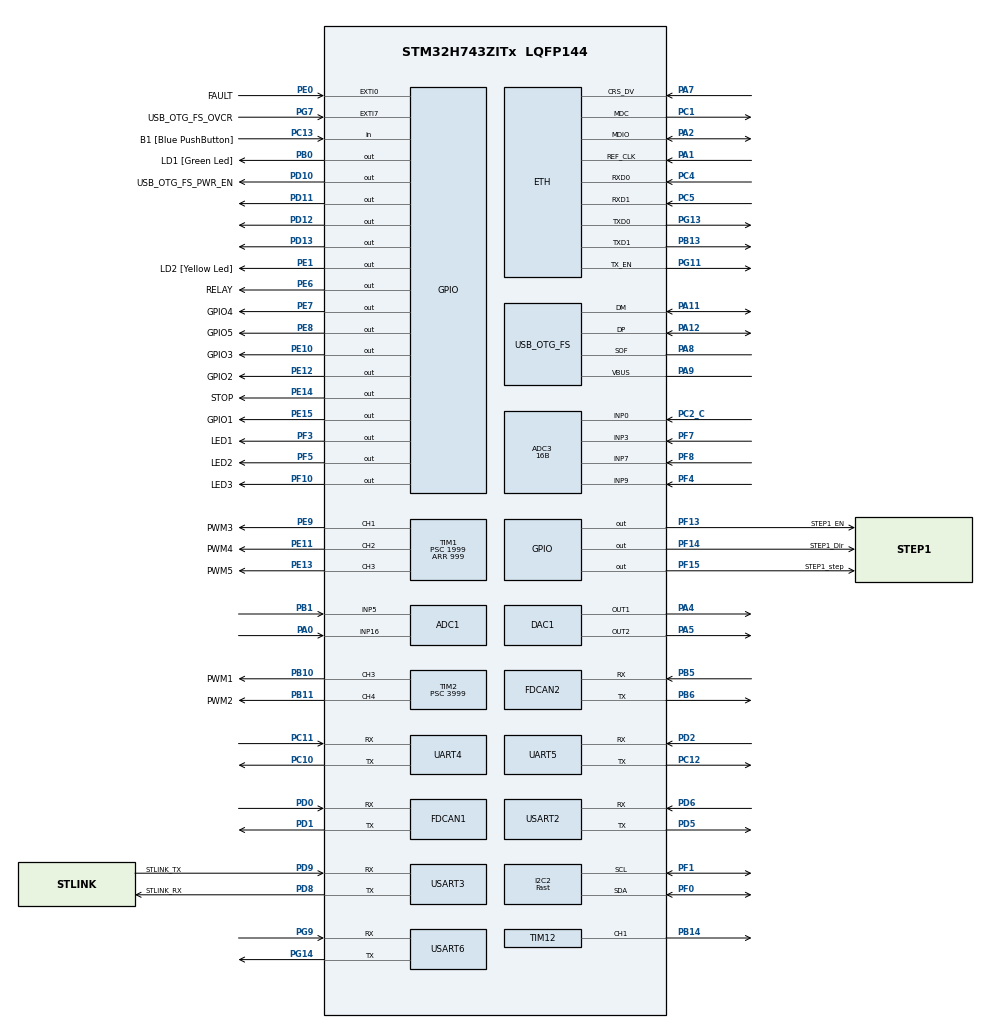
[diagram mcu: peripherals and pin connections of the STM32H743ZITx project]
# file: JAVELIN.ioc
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ADC1.Channel-0\#ChannelRegularConversion=ADC_CHANNEL_5
ADC1.NbrOfConversionFlag=1
ADC1.OffsetNumber-0\#ChannelRegularConversion=ADC_OFFSET_NONE
ADC1.OffsetSignedSaturation-0\#ChannelRegularConversion=DISABLE
ADC1.Rank-0\#ChannelRegularConversion=1
ADC1.SamplingTime-0\#ChannelRegularConversion=ADC_SAMPLETIME_1CYCLE_5
ADC1.master=1
ADC3.Channel-23\#ChannelRegularConversion=ADC_CHANNEL_TEMPSENSOR
ADC3.Channel-24\#ChannelRegularConversion=ADC_CHANNEL_VBAT
ADC3.Channel-25\#ChannelRegularConversion=ADC_CHANNEL_VREFINT
ADC3.ClockPrescalerADC3=ADC_CLOCK_ASYNC_DIV1
ADC3.NbrOfConversion=3
ADC3.NbrOfConversionFlag=1
ADC3.OffsetNumber-23\#ChannelRegularConversion=ADC_OFFSET_NONE
ADC3.OffsetNumber-24\#ChannelRegularConversion=ADC_OFFSET_NONE
ADC3.OffsetNumber-25\#ChannelRegularConversion=ADC_OFFSET_NONE
ADC3.OffsetSignedSaturation-23\#ChannelRegularConversion=DISABLE
ADC3.OffsetSignedSaturation-24\#ChannelRegularConversion=DISABLE
ADC3.OffsetSignedSaturation-25\#ChannelRegularConversion=DISABLE
ADC3.OversamplingMode=ENABLE
ADC3.Rank-23\#ChannelRegularConversion=1
ADC3.Rank-24\#ChannelRegularConversion=2
ADC3.Rank-25\#ChannelRegularConversion=3
ADC3.Ratio=2
ADC3.Resolution=ADC_RESOLUTION_16B
ADC3.SamplingTime-23\#ChannelRegularConversion=ADC_SAMPLETIME_387CYCLES_5
ADC3.SamplingTime-24\#ChannelRegularConversion=ADC_SAMPLETIME_32CYCLES_5
ADC3.SamplingTime-25\#ChannelRegularConversion=ADC_SAMPLETIME_32CYCLES_5
CORTEX_M7.AccessPermission-Cortex_Memory_Protection_Unit_Region0_Settings=MPU_REGION_FULL_ACCESS
CORTEX_M7.AccessPermission-Cortex_Memory_Protection_Unit_Region1_Settings=MPU_REGION_FULL_ACCESS
CORTEX_M7.BaseAddress-Cortex_Memory_Protection_Unit_Region0_Settings=0x30040000
CORTEX_M7.BaseAddress-Cortex_Memory_Protection_Unit_Region1_Settings=0x30040000
CORTEX_M7.CPU_DCache=Enabled
CORTEX_M7.CPU_ICache=Enabled
CORTEX_M7.DisableExec-Cortex_Memory_Protection_Unit_Region0_Settings=MPU_INSTRUCTION_ACCESS_DISABLE
CORTEX_M7.DisableExec-Cortex_Memory_Protection_Unit_Region1_Settings=MPU_INSTRUCTION_ACCESS_DISABLE
CORTEX_M7.Enable-Cortex_Memory_Protection_Unit_Region0_Settings=MPU_REGION_ENABLE
CORTEX_M7.Enable-Cortex_Memory_Protection_Unit_Region1_Settings=MPU_REGION_ENABLE
CORTEX_M7.IsBufferable-Cortex_Memory_Protection_Unit_Region1_Settings=MPU_ACCESS_BUFFERABLE
CORTEX_M7.IsShareable-Cortex_Memory_Protection_Unit_Region1_Settings=MPU_ACCESS_SHAREABLE
CORTEX_M7.MPU_Control=MPU_PRIVILEGED_DEFAULT
CORTEX_M7.Size-Cortex_Memory_Protection_Unit_Region0_Settings=MPU_REGION_SIZE_32KB
CORTEX_M7.Size-Cortex_Memory_Protection_Unit_Region1_Settings=MPU_REGION_SIZE_256B
CORTEX_M7.TypeExtField-Cortex_Memory_Protection_Unit_Region0_Settings=MPU_TEX_LEVEL1
DAC1.DAC_Channel-DAC_OUT1=DAC_CHANNEL_1
DAC1.DAC_Channel-DAC_OUT2=DAC_CHANNEL_2
ETH.MediaInterface=HAL_ETH_RMII_MODE
FDCAN1.CalculateBaudRateNominal=312500
FDCAN1.CalculateTimeBitNominal=3200
FDCAN1.CalculateTimeQuantumNominal=640.0
FDCAN2.CalculateBaudRateNominal=312500
FDCAN2.CalculateTimeBitNominal=3200
FDCAN2.CalculateTimeQuantumNominal=640.0
FREERTOS.Queues01=RX_msg_queue,32,uint16_t,0,Dynamic,NULL,NULL
FREERTOS.Tasks01=defaultTask,24,256,StartDefaultTask,Default,NULL,Dynamic,NULL,NULL;Blink,8,128,Blink_Init,Default,NULL,Dynamic,NULL,NULL;IDWGTrigger,40,128,IDWGTrigger_Init,Default,NULL,Dynamic,NULL,NULL;ADCPoll,8,128,ADCPoll_Init,Default,NULL,Dynamic,NULL,NULL;PSFunctions,8,128,PSFunctions_Init,Default,NULL,Dynamic,NULL,NULL;SSFunctions,8,128,SSFunctions_Init,Default,NULL,Dynamic,NULL,NULL;DSFunctions,8,128,DSFunctions_Init,Default,NULL,Dynamic,NULL,NULL
FREERTOS.configENABLE_FPU=1
FREERTOS.configGENERATE_RUN_TIME_STATS=1
FREERTOS.configRECORD_STACK_HIGH_ADDRESS=1
FREERTOS.configTOTAL_HEAP_SIZE=65536
FREERTOS.configUSE_NEWLIB_REENTRANT=1
FREERTOS.configUSE_STATS_FORMATTING_FUNCTIONS=1
I2C2.I2C_Speed_Mode=I2C_Fast
I2C2.Timing=0x009034B6
IWDG1.Prescaler=IWDG_PRESCALER_16
LWIP.BSP.number=1
LWIP.CHECKSUM_CHECK_TCP=1
LWIP.CHECKSUM_GEN_TCP=1
LWIP.DEFAULT_THREAD_STACKSIZE=16360
LWIP.GATEWAY_ADDRESS=192.168.000.001
LWIP.IP_ADDRESS=192.168.000.123
LWIP.LWIP_DHCP=0
LWIP.MEM_SIZE=16360
LWIP.NETMASK_ADDRESS=255.255.255.000
LWIP.PBUF_POOL_BUFSIZE=16360
LWIP.PBUF_POOL_SIZE=12
LWIP.Version=v2.1.2_Cube
LWIP0.BSP.STBoard=false
LWIP0.BSP.api=BSP_COMPONENT_DRIVER
LWIP0.BSP.component=LAN8742
LWIP0.BSP.instance=LAN8742
LWIP0.BSP.name=Driver_PHY
LWIP0.BSP.semaphore=S_LAN8742
LWIP0.BSP.solution=LAN8742
Mcu.Family=STM32H7
Mcu.Name=STM32H743ZITx
Mcu.Package=LQFP144
NVIC.ETH_IRQn=true\:5\:0\:false\:false\:true\:true\:true\:true\:true
NVIC.PriorityGroup=NVIC_PRIORITYGROUP_4
NVIC.TIM16_IRQn=true\:5\:0\:false\:false\:true\:true\:true\:true\:true
NVIC.TIM17_IRQn=true\:15\:0\:false\:false\:true\:false\:false\:true\:true
NVIC.TimeBase=TIM17_IRQn
NVIC.TimeBaseIP=TIM17
PA0.Mode=IN16-Single-Ended
PA0.Signal=ADC1_INP16
PA1.GPIO_Speed=GPIO_SPEED_FREQ_VERY_HIGH
PA1.Mode=RMII
PA1.Signal=ETH_REF_CLK
PA11.Mode=Device_Only
PA11.Signal=USB_OTG_FS_DM
PA12.Mode=Device_Only
PA12.Signal=USB_OTG_FS_DP
PA13\ (JTMS/SWDIO).Mode=Serial_Wire
PA13\ (JTMS/SWDIO).Signal=DEBUG_JTMS-SWDIO
PA14\ (JTCK/SWCLK).Mode=Serial_Wire
PA14\ (JTCK/SWCLK).Signal=DEBUG_JTCK-SWCLK
PA2.GPIO_Speed=GPIO_SPEED_FREQ_VERY_HIGH
PA2.Mode=RMII
PA2.Signal=ETH_MDIO
PA4.Signal=COMP_DAC11_group
PA5.Signal=COMP_DAC12_group
PA7.GPIO_Speed=GPIO_SPEED_FREQ_VERY_HIGH
PA7.Mode=RMII
PA7.Signal=ETH_CRS_DV
PA8.Mode=Activate_SOF_FS
PA8.Signal=USB_OTG_FS_SOF
PA9.Mode=Activate_VBUS
PA9.Signal=USB_OTG_FS_VBUS
PB0.GPIO_Label=LD1 [Green Led]
PB0.Signal=GPIO_Output
PB1.Signal=ADCx_INP5
PB10.GPIO_Label=PWM1
PB10.Signal=S_TIM2_CH3
PB11.GPIO_Label=PWM2
PB11.Signal=S_TIM2_CH4
PB13.GPIO_Speed=GPIO_SPEED_FREQ_VERY_HIGH
PB13.Mode=RMII
PB13.Signal=ETH_TXD1
PB14.Signal=S_TIM12_CH1
PB5.Mode=FDCAN_Activate
PB5.Signal=FDCAN2_RX
PB6.Mode=FDCAN_Activate
PB6.Signal=FDCAN2_TX
PC1.GPIO_Speed=GPIO_SPEED_FREQ_VERY_HIGH
PC1.Mode=RMII
PC1.Signal=ETH_MDC
PC10.Mode=Asynchronous
PC10.Signal=UART4_TX
PC11.Mode=Asynchronous
PC11.Signal=UART4_RX
PC12.Mode=Asynchronous
PC12.Signal=UART5_TX
PC13.GPIO_Label=B1 [Blue PushButton]
PC13.Signal=GPIO_Input
PC14-OSC32_IN\ (OSC32_IN).Mode=LSE-External-Oscillator
PC14-OSC32_IN\ (OSC32_IN).Signal=RCC_OSC32_IN
PC15-OSC32_OUT\ (OSC32_OUT).Mode=LSE-External-Oscillator
PC15-OSC32_OUT\ (OSC32_OUT).Signal=RCC_OSC32_OUT
PC2_C.Mode=IN0-Single-Ended
PC2_C.Signal=ADC3_INP0
PC4.GPIO_Speed=GPIO_SPEED_FREQ_VERY_HIGH
PC4.Mode=RMII
PC4.Signal=ETH_RXD0
PC5.GPIO_Speed=GPIO_SPEED_FREQ_VERY_HIGH
PC5.Mode=RMII
PC5.Signal=ETH_RXD1
PD0.Mode=FDCAN_Activate
PD0.Signal=FDCAN1_RX
PD1.Mode=FDCAN_Activate
PD1.Signal=FDCAN1_TX
PD10.GPIO_Label=USB_OTG_FS_PWR_EN
PD10.Signal=GPIO_Output
PD11.Signal=GPIO_Output
PD12.Signal=GPIO_Output
PD13.Signal=GPIO_Output
PD2.Mode=Asynchronous
PD2.Signal=UART5_RX
PD5.Mode=Asynchronous
PD5.Signal=USART2_TX
PD6.Mode=Asynchronous
PD6.Signal=USART2_RX
PD8.GPIO_Label=STLINK_RX
PD8.Mode=Asynchronous
PD8.Signal=USART3_TX
PD9.GPIO_Label=STLINK_TX
PD9.Mode=Asynchronous
PD9.Signal=USART3_RX
PE0.GPIO_Label=FAULT
PE0.Signal=GPXTI0
PE1.GPIO_Label=LD2 [Yellow Led]
PE1.Signal=GPIO_Output
PE10.GPIO_Label=GPIO3
PE10.Signal=GPIO_Output
PE11.GPIO_Label=PWM4
PE11.Signal=S_TIM1_CH2
PE12.GPIO_Label=GPIO2
PE12.Signal=GPIO_Output
PE13.GPIO_Label=PWM5
PE13.Signal=S_TIM1_CH3
PE14.GPIO_Label=STOP
PE14.Signal=GPIO_Output
PE15.GPIO_Label=GPIO1
PE15.Signal=GPIO_Output
PE6.GPIO_Label=RELAY
PE6.Signal=GPIO_Output
PE7.GPIO_Label=GPIO4
PE7.Signal=GPIO_Output
PE8.GPIO_Label=GPIO5
PE8.Signal=GPIO_Output
PE9.GPIO_Label=PWM3
PE9.Signal=S_TIM1_CH1
PF0.Mode=I2C
PF0.Signal=I2C2_SDA
PF1.Mode=I2C
PF1.Signal=I2C2_SCL
PF10.GPIO_Label=LED3
PF10.Signal=GPIO_Output
PF13.GPIO_Label=STEP1_EN
PF13.Signal=GPIO_Output
PF14.GPIO_Label=STEP1_Dir
PF14.Signal=GPIO_Output
PF15.GPIO_Label=STEP1_step
PF15.Signal=GPIO_Output
PF3.GPIO_Label=LED1
PF3.Signal=GPIO_Output
PF4.Mode=IN9-Single-Ended
PF4.Signal=ADC3_INP9
PF5.GPIO_Label=LED2
PF5.Signal=GPIO_Output
PF7.Mode=IN3-Single-Ended
PF7.Signal=ADC3_INP3
PF8.Mode=IN7-Single-Ended
PF8.Signal=ADC3_INP7
PG11.GPIO_Speed=GPIO_SPEED_FREQ_VERY_HIGH
PG11.Mode=RMII
PG11.Signal=ETH_TX_EN
PG13.GPIO_Speed=GPIO_SPEED_FREQ_VERY_HIGH
PG13.Mode=RMII
PG13.Signal=ETH_TXD0
PG14.Mode=Asynchronous
PG14.Signal=USART6_TX
PG7.GPIO_Label=USB_OTG_FS_OVCR
PG7.Signal=GPXTI7
PG9.Mode=Asynchronous
PG9.Signal=USART6_RX
PH0-OSC_IN\ (PH0).Mode=HSE-External-Oscillator
PH0-OSC_IN\ (PH0).Signal=RCC_OSC_IN
PH1-OSC_OUT\ (PH1).Mode=HSE-External-Oscillator
PH1-OSC_OUT\ (PH1).Signal=RCC_OSC_OUT
ProjectManager.HeapSize=0x200
ProjectManager.StackSize=0x400
ProjectManager.TargetToolchain=STM32CubeIDE
RCC.ADCFreq_Value=100000000
RCC.APB1Freq_Value=100000000
RCC.APB2Freq_Value=100000000
RCC.APB3Freq_Value=100000000
RCC.APB4Freq_Value=100000000
RCC.CortexFreq_Value=400000000
RCC.D1PPRE=RCC_APB3_DIV2
RCC.D2PPRE1=RCC_APB1_DIV2
RCC.D2PPRE2=RCC_APB2_DIV2
RCC.D3PPRE=RCC_APB4_DIV2
RCC.DIVM1=10
RCC.DIVN1=125
RCC.DIVN2=100
RCC.FDCANCLockSelection=RCC_FDCANCLKSOURCE_HSE
RCC.HCLKFreq_Value=200000000
RCC.HPRE=RCC_HCLK_DIV2
RCC.HSE_VALUE=25000000
RCC.SPI123CLockSelection=RCC_SPI123CLKSOURCE_PLL2
RCC.SYSCLKFreq_VALUE=400000000
RCC.SYSCLKSource=RCC_SYSCLKSOURCE_PLLCLK
RCC.USBCLockSelection=RCC_USBCLKSOURCE_HSI48
RCC.USBFreq_Value=48000000
SH.ADCx_INP5.0=ADC1_INP5,IN5-Single-Ended
SH.COMP_DAC11_group.0=DAC1_OUT1,DAC_OUT1
SH.COMP_DAC12_group.0=DAC1_OUT2,DAC_OUT2
SH.S_TIM12_CH1.0=TIM12_CH1,PWM Generation1 CH1
SH.S_TIM1_CH1.0=TIM1_CH1,PWM Generation1 CH1
SH.S_TIM1_CH2.0=TIM1_CH2,PWM Generation2 CH2
SH.S_TIM1_CH3.0=TIM1_CH3,PWM Generation3 CH3
SH.S_TIM2_CH3.0=TIM2_CH3,PWM Generation3 CH3
SH.S_TIM2_CH4.0=TIM2_CH4,PWM Generation4 CH4
TIM1.Channel-PWM\ Generation1\ CH1=TIM_CHANNEL_1
TIM1.Channel-PWM\ Generation2\ CH2=TIM_CHANNEL_2
TIM1.Channel-PWM\ Generation3\ CH3=TIM_CHANNEL_3
TIM1.Period=999
TIM1.Prescaler=1999
TIM12.AutoReloadPreload=TIM_AUTORELOAD_PRELOAD_ENABLE
TIM12.Channel-PWM\ Generation1\ CH1=TIM_CHANNEL_1
TIM12.Period=999
TIM12.Prescaler=1999
TIM16.AutoReloadPreload=TIM_AUTORELOAD_PRELOAD_ENABLE
TIM2.Channel-PWM\ Generation3\ CH3=TIM_CHANNEL_3
TIM2.Channel-PWM\ Generation4\ CH4=TIM_CHANNEL_4
TIM2.Period=999
TIM2.Prescaler=3999
USART2.VirtualMode-Asynchronous=VM_ASYNC
USART3.VirtualMode-Asynchronous=VM_ASYNC
USART6.VirtualMode-Asynchronous=VM_ASYNC
USB_OTG_FS.VirtualMode=Device_Only
VP_ADC3_TempSens_Input.Mode=IN-TempSens
VP_ADC3_Vbat_Input.Mode=IN-Vbat
VP_ADC3_Vref_Input.Mode=IN-Vrefint
VP_FREERTOS_VS_CMSIS_V2.Mode=CMSIS_V2
VP_IWDG1_VS_IWDG.Mode=IWDG_Activate
VP_LWIP_VS_Enabled.Mode=Enabled
VP_SYS_VS_tim17.Mode=TIM17
VP_TIM16_VS_ClockSourceINT.Mode=Enable_Timer
board=NUCLEO-H743ZI2

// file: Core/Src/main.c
/* USER CODE BEGIN Header */
/**
  ******************************************************************************
  * @file           : main.c
  * @brief          : Main program body
  ******************************************************************************
  * @attention
  *
  * Copyright (c) 2022 STMicroelectronics.
  * All rights reserved.
  *
  * This software is licensed under terms that can be found in the LICENSE file
  * in the root directory of this software component.
  * If no LICENSE file comes with this software, it is provided AS-IS.
  *
  ******************************************************************************
  */
/* USER CODE END Header */
#include "main.h"
#include "cmsis_os.h"
#include "adc.h"
#include "dac.h"
#include "fdcan.h"
#include "i2c.h"
#include "iwdg.h"
#include "lwip.h"
#include "tim.h"
#include "usart.h"
#include "usb_otg.h"
#include "gpio.h"

void SystemClock_Config(void);
void PeriphCommonClock_Config(void);
static void MPU_Config(void);
void MX_FREERTOS_Init(void);

int main(void)
{

  /* MPU Configuration--------------------------------------------------------*/
  MPU_Config();

  /* Enable I-Cache---------------------------------------------------------*/
  SCB_EnableICache();

  /* Enable D-Cache---------------------------------------------------------*/
  SCB_EnableDCache();

  /* MCU Configuration--------------------------------------------------------*/

  /* Reset of all peripherals, Initializes the Flash interface and the Systick. */
  HAL_Init();

  /* Configure the system clock */
  SystemClock_Config();

/* Configure the peripherals common clocks */
  PeriphCommonClock_Config();

  /* Initialize all configured peripherals */
  MX_GPIO_Init();
  MX_USART3_UART_Init();
  MX_IWDG1_Init();
  MX_FDCAN1_Init();
  MX_FDCAN2_Init();
  MX_TIM12_Init();
  MX_TIM16_Init();
  MX_ADC3_Init();
  MX_ADC1_Init();
  MX_I2C2_Init();
  MX_TIM1_Init();
  MX_TIM2_Init();
  MX_UART4_Init();
  MX_USART2_UART_Init();
  MX_DAC1_Init();
  MX_UART5_Init();
  MX_USART6_UART_Init();
  MX_USB_OTG_FS_PCD_Init();
  /* USER CODE BEGIN 2 */
  HAL_UART_Transmit(&huart3, "plz\n\r", 6, 10);

  HAL_TIM_PWM_Start(&htim12, TIM_CHANNEL_1);
  HAL_TIM_PWM_Start(&htim2,TIM_CHANNEL_3);
  //TIM12->CCR1 = TIM12->ARR *120/255;

    HAL_ADCEx_Calibration_Start(&hadc3,ADC_CALIB_OFFSET,ADC_SINGLE_ENDED);
  /* USER CODE END 2 */

  /* Init scheduler */
  osKernelInitialize();  /* Call init function for freertos objects (in freertos.c) */
  MX_FREERTOS_Init();

  /* Start scheduler */
  osKernelStart();

  /* We should never get here as control is now taken by the scheduler */
  /* Infinite loop */
  while (1)
  {

  }
}

void SystemClock_Config(void)
{
  RCC_OscInitTypeDef RCC_OscInitStruct = {0};
  RCC_ClkInitTypeDef RCC_ClkInitStruct = {0};

  /** Supply configuration update enable
  */
  HAL_PWREx_ConfigSupply(PWR_LDO_SUPPLY);

  /** Configure the main internal regulator output voltage
  */
  __HAL_PWR_VOLTAGESCALING_CONFIG(PWR_REGULATOR_VOLTAGE_SCALE1);

  while(!__HAL_PWR_GET_FLAG(PWR_FLAG_VOSRDY)) {}

  /** Macro to configure the PLL clock source
  */
  __HAL_RCC_PLL_PLLSOURCE_CONFIG(RCC_PLLSOURCE_HSI);

  /** Initializes the RCC Oscillators according to the specified parameters
  * in the RCC_OscInitTypeDef structure.
  */
  RCC_OscInitStruct.OscillatorType = RCC_OSCILLATORTYPE_HSI48|RCC_OSCILLATORTYPE_HSI
                              |RCC_OSCILLATORTYPE_LSI|RCC_OSCILLATORTYPE_HSE;
  RCC_OscInitStruct.HSEState = RCC_HSE_ON;
  RCC_OscInitStruct.HSIState = RCC_HSI_DIV1;
  RCC_OscInitStruct.HSICalibrationValue = RCC_HSICALIBRATION_DEFAULT;
  RCC_OscInitStruct.LSIState = RCC_LSI_ON;
  RCC_OscInitStruct.HSI48State = RCC_HSI48_ON;
  RCC_OscInitStruct.PLL.PLLState = RCC_PLL_ON;
  RCC_OscInitStruct.PLL.PLLSource = RCC_PLLSOURCE_HSI;
  RCC_OscInitStruct.PLL.PLLM = 10;
  RCC_OscInitStruct.PLL.PLLN = 125;
  RCC_OscInitStruct.PLL.PLLP = 2;
  RCC_OscInitStruct.PLL.PLLQ = 2;
  RCC_OscInitStruct.PLL.PLLR = 2;
  RCC_OscInitStruct.PLL.PLLRGE = RCC_PLL1VCIRANGE_2;
  RCC_OscInitStruct.PLL.PLLVCOSEL = RCC_PLL1VCOWIDE;
  RCC_OscInitStruct.PLL.PLLFRACN = 0;
  if (HAL_RCC_OscConfig(&RCC_OscInitStruct) != HAL_OK)
  {
    Error_Handler();
  }

  /** Initializes the CPU, AHB and APB buses clocks
  */
  RCC_ClkInitStruct.ClockType = RCC_CLOCKTYPE_HCLK|RCC_CLOCKTYPE_SYSCLK
                              |RCC_CLOCKTYPE_PCLK1|RCC_CLOCKTYPE_PCLK2
                              |RCC_CLOCKTYPE_D3PCLK1|RCC_CLOCKTYPE_D1PCLK1;
  RCC_ClkInitStruct.SYSCLKSource = RCC_SYSCLKSOURCE_PLLCLK;
  RCC_ClkInitStruct.SYSCLKDivider = RCC_SYSCLK_DIV1;
  RCC_ClkInitStruct.AHBCLKDivider = RCC_HCLK_DIV2;
  RCC_ClkInitStruct.APB3CLKDivider = RCC_APB3_DIV2;
  RCC_ClkInitStruct.APB1CLKDivider = RCC_APB1_DIV2;
  RCC_ClkInitStruct.APB2CLKDivider = RCC_APB2_DIV2;
  RCC_ClkInitStruct.APB4CLKDivider = RCC_APB4_DIV2;

  if (HAL_RCC_ClockConfig(&RCC_ClkInitStruct, FLASH_LATENCY_2) != HAL_OK)
  {
    Error_Handler();
  }
}

void PeriphCommonClock_Config(void)
{
  RCC_PeriphCLKInitTypeDef PeriphClkInitStruct = {0};

  /** Initializes the peripherals clock
  */
  PeriphClkInitStruct.PeriphClockSelection = RCC_PERIPHCLK_ADC;
  PeriphClkInitStruct.PLL2.PLL2M = 32;
  PeriphClkInitStruct.PLL2.PLL2N = 100;
  PeriphClkInitStruct.PLL2.PLL2P = 2;
  PeriphClkInitStruct.PLL2.PLL2Q = 2;
  PeriphClkInitStruct.PLL2.PLL2R = 2;
  PeriphClkInitStruct.PLL2.PLL2RGE = RCC_PLL2VCIRANGE_1;
  PeriphClkInitStruct.PLL2.PLL2VCOSEL = RCC_PLL2VCOWIDE;
  PeriphClkInitStruct.PLL2.PLL2FRACN = 0;
  PeriphClkInitStruct.AdcClockSelection = RCC_ADCCLKSOURCE_PLL2;
  if (HAL_RCCEx_PeriphCLKConfig(&PeriphClkInitStruct) != HAL_OK)
  {
    Error_Handler();
  }
}

/* USER CODE BEGIN 4 */
volatile unsigned long ulHighFrequencyTimerTicks;

void configureTimerForRunTimeStats(void) {
  ulHighFrequencyTimerTicks = 0;
  HAL_TIM_Base_Start_IT(&htim16);
}

unsigned long getRunTimeCounterValue(void) {
  return ulHighFrequencyTimerTicks;
}

void HAL_ADC_ConvCpltCallback(ADC_HandleTypeDef* hadc)
{
    // Conversion Complete & DMA Transfer Complete As Well
    // So The AD_RES Is Now Updated & Let's Move IT To The PWM CCR1
    // Update The PWM Duty Cycle With Latest ADC Conversion Result
    HAL_UART_Transmit(&huart3,"LGTM\r\n",6,10);
}

/* USER CODE END 4 */

/* MPU Configuration */

void MPU_Config(void)
{
  MPU_Region_InitTypeDef MPU_InitStruct = {0};

  /* Disables the MPU */
  HAL_MPU_Disable();

  /** Initializes and configures the Region and the memory to be protected
  */
  MPU_InitStruct.Enable = MPU_REGION_ENABLE;
  MPU_InitStruct.Number = MPU_REGION_NUMBER0;
  MPU_InitStruct.BaseAddress = 0x30040000;
  MPU_InitStruct.Size = MPU_REGION_SIZE_32KB;
  MPU_InitStruct.SubRegionDisable = 0x0;
  MPU_InitStruct.TypeExtField = MPU_TEX_LEVEL1;
  MPU_InitStruct.AccessPermission = MPU_REGION_FULL_ACCESS;
  MPU_InitStruct.DisableExec = MPU_INSTRUCTION_ACCESS_DISABLE;
  MPU_InitStruct.IsShareable = MPU_ACCESS_NOT_SHAREABLE;
  MPU_InitStruct.IsCacheable = MPU_ACCESS_NOT_CACHEABLE;
  MPU_InitStruct.IsBufferable = MPU_ACCESS_NOT_BUFFERABLE;

  HAL_MPU_ConfigRegion(&MPU_InitStruct);

  /** Initializes and configures the Region and the memory to be protected
  */
  MPU_InitStruct.Number = MPU_REGION_NUMBER1;
  MPU_InitStruct.Size = MPU_REGION_SIZE_256B;
  MPU_InitStruct.TypeExtField = MPU_TEX_LEVEL0;
  MPU_InitStruct.IsShareable = MPU_ACCESS_SHAREABLE;
  MPU_InitStruct.IsBufferable = MPU_ACCESS_BUFFERABLE;

  HAL_MPU_ConfigRegion(&MPU_InitStruct);
  /* Enables the MPU */
  HAL_MPU_Enable(MPU_PRIVILEGED_DEFAULT);

}

void HAL_TIM_PeriodElapsedCallback(TIM_HandleTypeDef *htim)
{
  if (htim->Instance == TIM17) {
    HAL_IncTick();
  }
}

void Error_Handler(void)
{
  __disable_irq();
  while (1)
  {
  }
}

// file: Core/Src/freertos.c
/* USER CODE BEGIN Header */
/**
  ******************************************************************************
  * File Name          : freertos.c
  * Description        : Code for freertos applications
  ******************************************************************************
  * @attention
  *
  * Copyright (c) 2022 STMicroelectronics.
  * All rights reserved.
  *
  * This software is licensed under terms that can be found in the LICENSE file
  * in the root directory of this software component.
  * If no LICENSE file comes with this software, it is provided AS-IS.
  *
  ******************************************************************************
  */
/* USER CODE END Header */

#include "FreeRTOS.h"
#include "task.h"
#include "main.h"
#include "cmsis_os.h"

/* USER CODE BEGIN Includes */
#include "usart.h"
#include "tcpserver.h"
#include "iwdg.h"
#include "stdio.h"
#include "adc.h"
#include "TraxxasESC.h"
#include "Servo.h"
#include "MSGHandler.h"
#include "stepper.h"
/* USER CODE END Includes */

/* USER CODE BEGIN Variables */
volatile uint32_t adcval[3];
/* USER CODE END Variables */
/* Definitions for defaultTask */
osThreadId_t defaultTaskHandle;
const osThreadAttr_t defaultTask_attributes = {
  .name = "defaultTask",
  .stack_size = 256 * 4,
  .priority = (osPriority_t) osPriorityNormal,
};
/* Definitions for Blink */
osThreadId_t BlinkHandle;
const osThreadAttr_t Blink_attributes = {
  .name = "Blink",
  .stack_size = 128 * 4,
  .priority = (osPriority_t) osPriorityLow,
};
/* Definitions for IDWGTrigger */
osThreadId_t IDWGTriggerHandle;
const osThreadAttr_t IDWGTrigger_attributes = {
  .name = "IDWGTrigger",
  .stack_size = 128 * 4,
  .priority = (osPriority_t) osPriorityHigh,
};
/* Definitions for ADCPoll */
osThreadId_t ADCPollHandle;
const osThreadAttr_t ADCPoll_attributes = {
  .name = "ADCPoll",
  .stack_size = 128 * 4,
  .priority = (osPriority_t) osPriorityLow,
};
/* Definitions for PSFunctions */
osThreadId_t PSFunctionsHandle;
const osThreadAttr_t PSFunctions_attributes = {
  .name = "PSFunctions",
  .stack_size = 128 * 4,
  .priority = (osPriority_t) osPriorityLow,
};
/* Definitions for SSFunctions */
osThreadId_t SSFunctionsHandle;
const osThreadAttr_t SSFunctions_attributes = {
  .name = "SSFunctions",
  .stack_size = 128 * 4,
  .priority = (osPriority_t) osPriorityLow,
};
/* Definitions for DSFunctions */
osThreadId_t DSFunctionsHandle;
const osThreadAttr_t DSFunctions_attributes = {
  .name = "DSFunctions",
  .stack_size = 128 * 4,
  .priority = (osPriority_t) osPriorityLow,
};
/* Definitions for RX_msg_queue */

/* USER CODE BEGIN FunctionPrototypes */
osThreadId_t MSGProcessHandle;
const osThreadAttr_t MSGProcess_attributes = {
    .name ="MSGProcess",
    .stack_size = 128*4,
    .priority = (osPriority_t) osPriorityLow,
};

/* USER CODE END FunctionPrototypes */

void StartDefaultTask(void *argument);
void Blink_Init(void *argument);
void IDWGTrigger_Init(void *argument);
void ADCPoll_Init(void *argument);
void PSFunctions_Init(void *argument);
void SSFunctions_Init(void *argument);
void DSFunctions_Init(void *argument);

extern void MX_LWIP_Init(void);
void MX_FREERTOS_Init(void); /* (MISRA C 2004 rule 8.1) */

/* Hook prototypes */
void configureTimerForRunTimeStats(void);
unsigned long getRunTimeCounterValue(void);

/* USER CODE BEGIN 1 */
void MSGProcess_Init(void *argument);
/* Functions needed when configGENERATE_RUN_TIME_STATS is on */
__weak void configureTimerForRunTimeStats(void)
{

}

__weak unsigned long getRunTimeCounterValue(void)
{
return 0;
}
/* USER CODE END 1 */

void MX_FREERTOS_Init(void) {

  /* Create the queue(s) */
  /* creation of RX_msg_queue */

  /* Create the thread(s) */
  /* creation of defaultTask */
  defaultTaskHandle = osThreadNew(StartDefaultTask, NULL, &defaultTask_attributes);

  /* creation of Blink */
  BlinkHandle = osThreadNew(Blink_Init, NULL, &Blink_attributes);

  /* creation of IDWGTrigger */
  IDWGTriggerHandle = osThreadNew(IDWGTrigger_Init, NULL, &IDWGTrigger_attributes);

  /* creation of ADCPoll */
  ADCPollHandle = osThreadNew(ADCPoll_Init, NULL, &ADCPoll_attributes);

  /* creation of PSFunctions */
  PSFunctionsHandle = osThreadNew(PSFunctions_Init, NULL, &PSFunctions_attributes);

  /* creation of SSFunctions */
  SSFunctionsHandle = osThreadNew(SSFunctions_Init, NULL, &SSFunctions_attributes);

  /* creation of DSFunctions */
  DSFunctionsHandle = osThreadNew(DSFunctions_Init, NULL, &DSFunctions_attributes);

  /* USER CODE BEGIN RTOS_THREADS */
  /* add threads, ... */
  MSGProcessHandle = osThreadNew(MSGProcess_Init,NULL,&MSGProcess_attributes);
  /* USER CODE END RTOS_THREADS */

}

void StartDefaultTask(void *argument)
{
  /* init code for LWIP */
  MX_LWIP_Init();
  /* USER CODE BEGIN StartDefaultTask */
 // osThreadDef(TCPServer, tcpserver_init, osPriorityNormal, 0, 1024);
 // TCPServerHandle = osThreadCreate(osThread(TCPServer), NULL);
  tcpserver_init();
  /* Infinite loop */

  for(;;)
  {
  /*    JAVMSG_t MSG;
      MSG.id = 0x12;
      MSG.Byte2 = 0x01;
      MSG.Byte3 = 0x01;
      MSG.Byte4 = 0x01;
      MSG.Byte5 = 0x01;
      MSG.Byte6 = 0x01;
      MSG.Byte7 = 0x01;
      MSG.Byte8 = 0x01;

    //  osMessageQueuePut(RX_msg_queueHandle,&MSG,0,0);
    //  osThreadYield();*/
      osDelay(1000);
  }
  /* USER CODE END StartDefaultTask */
}

/* USER CODE BEGIN Header_Blink_Init */
#define TEMPSENSOR_CAL1_ADDR ((uint16_t*) (0x1FF1E820U)
#define TEMPSENSOR_CAL2_ADDR ((uint16_t*) (0x1FF1E840U)
#define TEMPSENSOR_CAL1_TEMP (( int32_t)   30)
#define TEMPSENSOR_CAL2_TEMP (( int32_t)  110)
/**
* @brief Function implementing the Blink thread.
* @param argument: Not used
* @retval None
*/
/* USER CODE END Header_Blink_Init */
void Blink_Init(void *argument)
{
  /* USER CODE BEGIN Blink_Init */
  /* Infinite loop */
    //float tempcal = (TEMPSENSOR_CAL2_TEMP-TEMPSENSOR_CAL1_TEMP) /( (uint32_t) *TEMPSENSOR_CAL2_ADDR)  -   (uint32_t) *TEMPSENSOR_CAL1_ADDR)   ) ;

	uint32_t cnt = 1;
    char msg[100];
    uint32_t tick;
    float vref,vbat,temp;
    osDelay(1000);

    JAVMSG_t jav;

  for(;;)
  {
	  tick=  osKernelGetTickCount();
	 // int len = sprintf(msg,"MS Since last issue :%d\n\r",tick);
      //nt len = sprintf(msg,"MS Since last issue :%d Temp =%f Vbat = %f vref = %f\n\r",tick,temp,vbat,vref );

      cnt = osMessageQueueGetCount(RX_msg_queueHandle);
      int len = sprintf(msg,"uptime (ms) %d | queue length = %d |\n\r",tick ,cnt);
      HAL_UART_Transmit(&huart3, msg,len , 100);

    osDelay(1000);
  }
  /* USER CODE END Blink_Init */
}

/* USER CODE BEGIN Header_IDWGTrigger_InitosThreadYield();  */
/* USER CODE END Header_IDWGTrigger_Init */
void IDWGTrigger_Init(void *argument)
{
  /* USER CODE BEGIN IDWGTrigger_Init */
  /* Infinite loop */
  for(;;)
  {
      HAL_IWDG_Refresh(&hiwdg1);
    osDelay(1);

  }
  /* USER CODE END IDWGTrigger_Init */
}

/* USER CODE BEGIN Header_ADCPoll_Init */

uint32_t ADC3_Chnls[3] = {ADC_CHANNEL_TEMPSENSOR,ADC_CHANNEL_VBAT,ADC_CHANNEL_VREFINT};

void ADC_ChnlSel(ADC_HandleTypeDef *hadc, int Chnl){

    ADC_ChannelConfTypeDef sConfig = {0};

    sConfig.Channel = ADC3_Chnls[Chnl];
    //sConfig.Channel = ADC_CHANNEL_TEMPSENSOR;
    sConfig.Rank = ADC_REGULAR_RANK_1;
    sConfig.SamplingTime = ADC_SAMPLETIME_387CYCLES_5;
    sConfig.SingleDiff = ADC_SINGLE_ENDED;
    sConfig.OffsetNumber = ADC_OFFSET_NONE;
    sConfig.Offset = 0;
    sConfig.OffsetSignedSaturation = DISABLE;
    if (HAL_ADC_ConfigChannel(&hadc3, &sConfig) != HAL_OK)
    {
        Error_Handler();
    }

}

/**
* @brief Function implementing the ADCPoll thread.
* @param argument: Not used
* @retval None
 * TODO calculate time to see if all can be converted in one go
*/
/* USER CODE END Header_ADCPoll_Init */
void ADCPoll_Init(void *argument)
{
  /* USER CODE BEGIN ADCPoll_Init */
  /* Infinite loop */
    int adcchnl = 0;
    HAL_ADC_Start(&hadc3);
    HAL_ADC_PollForConversion(&hadc3, 100);
  for(;;)
  {
         adcval[adcchnl] = HAL_ADC_GetValue(&hadc3);
         HAL_ADC_Stop(&hadc3);

         adcchnl++;
         if(adcchnl >2){
             adcchnl = 0;
         }
         ADC_ChnlSel(&hadc3,adcchnl);
         HAL_ADC_Start(&hadc3);
         HAL_ADC_PollForConversion(&hadc3, 100);

    osDelay(1);
  }
  /* USER CODE END ADCPoll_Init */
}

void PSFunctions_Init(void *argument)
{
  /* USER CODE BEGIN PSFunctions_Init */
  /* Infinite loop */

    STR.rawMIN=120;
    STR.rawMAX=200;
    STR.degMAX = 90;
    STR.chl= 3;
    STR.htim = &htim2;
    STR.degMSG = 0;
    HAL_TIM_PWM_Start(&htim2,TIM_CHANNEL_3);

    LED.reverseLockOut=notCleared;
    LED.state =UnArmed;
    LED.rawMIN=0;
    LED.rawMAX=TIM12->ARR;
    LED.MAXIMUMOVERDRIVE = 100;
    LED.direction=Forward;
    LED.PWM_CHNL= 1;
    LED.htim = &htim12;

    DRV.reverseLockOut=notCleared;
    DRV.state =UnArmed;
    DRV.msgPwr=0;
    DRV.rawMIN=100;
    DRV.rawMAX=200;
    DRV.MAXIMUMOVERDRIVE = 100;
    DRV.direction=Forward;
    DRV.PWM_CHNL= 4;
    DRV.htim = &htim2; //PWM2
    HAL_TIM_PWM_Start(&htim2,TIM_CHANNEL_4);
    armESC_RTOS(&DRV);

  for(;;)
  {
      setPower(&DRV,DRV.msgPwr,Arming);
      servo_Set(&STR,STR.degMSG);
      osDelay(1);
  }
  /* USER CODE END PSFunctions_Init */
}

void SSFunctions_Init(void *argument)
{
  for(;;)
  {
  }
}

void DSFunctions_Init(void *argument)
{
  /* USER CODE BEGIN DSFunctions_Init */
  /* Infinite loop */

    SRC.pos =0;
    SRC.des =0;
    SRC.StepPort =STEP1_step_GPIO_Port;
    SRC.StepPin = STEP1_step_Pin;
    SRC.DirPort = STEP1_Dir_GPIO_Port;
    SRC.DirPin =STEP1_Dir_Pin;
    SRC.EnPort = STEP1_EN_GPIO_Port;
    SRC.EnPin =STEP1_EN_Pin;
    SRC.enabled = 0;
    SRC.dir = 0;
    SRC.state = 0;
    SRC.step = 0;

  for(;;)
  {

    //  StepUpdate(&SRC,SRC.des);
     // StepUpdate(&SRN,SRN.des);

    osDelay(1);
  }
  /* USER CODE END DSFunctions_Init */
}

/* USER CODE BEGIN Application */

void MSGProcess_Init(void *argument){

    MSGinit();
    lastRecMsg = 0;
    for(;;){

        if(  osKernelGetTickCount() > lastRecMsg +2000){
            DRV.msgPwr = 0;
            setPower(&DRV,0,Arming);
        }
        osDelay(1);

        MSGHandleLoop();
    }
}
/* USER CODE END Application */
